# StarFive VisionFive 2 v1.3b register map
File version: 0.1
Registers are 32-bit, read-write, no defined reset value unless marked. A register's access mark holds for its fields unless they carry their own. Offsets are from the block's base; [hi:lo] are bit positions; {n}, {i} and the like mark numbered series.

## starfive_jh7110_sys_pinctrl_0 (part 3 of 3) — From starfive,jh7110-sys-pinctrl, peripheral generator
Base 0x13040000
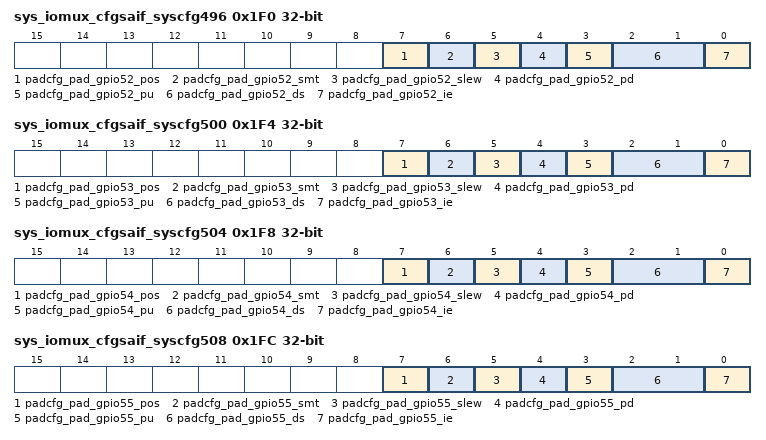
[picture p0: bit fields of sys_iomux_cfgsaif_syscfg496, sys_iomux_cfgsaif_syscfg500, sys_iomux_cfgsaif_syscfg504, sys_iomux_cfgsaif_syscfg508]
0x1F0 sys_iomux_cfgsaif_syscfg496
  [7] padcfg_pad_gpio52_pos — Power-on-Start (POS) enabler - 1: Enable active pull down for loss of core power, 0: Active pull-down capability disabled
  [6] padcfg_pad_gpio52_smt — Active high Schmitt (SMT) trigger selector - 0: No hysteresis, 1: Schmitt trigger ebabled
  [5] padcfg_pad_gpio52_slew — Slew Rate Control - 0: Slow (Half frequency), 1: Fast
  [4] padcfg_pad_gpio52_pd — Pull-Down (PD) settings - 1: Yes, 0: No
  [3] padcfg_pad_gpio52_pu — Pull-Up (PU) settings - 1: Yes, 0: No
  [2:1] padcfg_pad_gpio52_ds — Output Drive Strength (DS) - 00: The rated drive strength is 2 mA, 01: The rated drive strength is 4 mA, 10: The rated drive strength is 8 mA, 11: The rated drive strength is 12 mA
  [0] padcfg_pad_gpio52_ie — Input Enable (IE) Controller - 1: Enable the receiver, 0: Disable the receiver
0x1F4 sys_iomux_cfgsaif_syscfg500
  [7] padcfg_pad_gpio53_pos — Power-on-Start (POS) enabler - 1: Enable active pull down for loss of core power, 0: Active pull-down capability disabled
  [6] padcfg_pad_gpio53_smt — Active high Schmitt (SMT) trigger selector - 0: No hysteresis, 1: Schmitt trigger ebabled
  [5] padcfg_pad_gpio53_slew — Slew Rate Control - 0: Slow (Half frequency), 1: Fast
  [4] padcfg_pad_gpio53_pd — Pull-Down (PD) settings - 1: Yes, 0: No
  [3] padcfg_pad_gpio53_pu — Pull-Up (PU) settings - 1: Yes, 0: No
  [2:1] padcfg_pad_gpio53_ds — Output Drive Strength (DS) - 00: The rated drive strength is 2 mA, 01: The rated drive strength is 4 mA, 10: The rated drive strength is 8 mA, 11: The rated drive strength is 12 mA
  [0] padcfg_pad_gpio53_ie — Input Enable (IE) Controller - 1: Enable the receiver, 0: Disable the receiver
0x1F8 sys_iomux_cfgsaif_syscfg504
  [7] padcfg_pad_gpio54_pos — Power-on-Start (POS) enabler - 1: Enable active pull down for loss of core power, 0: Active pull-down capability disabled
  [6] padcfg_pad_gpio54_smt — Active high Schmitt (SMT) trigger selector - 0: No hysteresis, 1: Schmitt trigger ebabled
  [5] padcfg_pad_gpio54_slew — Slew Rate Control - 0: Slow (Half frequency), 1: Fast
  [4] padcfg_pad_gpio54_pd — Pull-Down (PD) settings - 1: Yes, 0: No
  [3] padcfg_pad_gpio54_pu — Pull-Up (PU) settings - 1: Yes, 0: No
  [2:1] padcfg_pad_gpio54_ds — Output Drive Strength (DS) - 00: The rated drive strength is 2 mA, 01: The rated drive strength is 4 mA, 10: The rated drive strength is 8 mA, 11: The rated drive strength is 12 mA
  [0] padcfg_pad_gpio54_ie — Input Enable (IE) Controller - 1: Enable the receiver, 0: Disable the receiver
0x1FC sys_iomux_cfgsaif_syscfg508
  [7] padcfg_pad_gpio55_pos — Power-on-Start (POS) enabler - 1: Enable active pull down for loss of core power, 0: Active pull-down capability disabled
  [6] padcfg_pad_gpio55_smt — Active high Schmitt (SMT) trigger selector - 0: No hysteresis, 1: Schmitt trigger ebabled
  [5] padcfg_pad_gpio55_slew — Slew Rate Control - 0: Slow (Half frequency), 1: Fast
  [4] padcfg_pad_gpio55_pd — Pull-Down (PD) settings - 1: Yes, 0: No
  [3] padcfg_pad_gpio55_pu — Pull-Up (PU) settings - 1: Yes, 0: No
  [2:1] padcfg_pad_gpio55_ds — Output Drive Strength (DS) - 00: The rated drive strength is 2 mA, 01: The rated drive strength is 4 mA, 10: The rated drive strength is 8 mA, 11: The rated drive strength is 12 mA
  [0] padcfg_pad_gpio55_ie — Input Enable (IE) Controller - 1: Enable the receiver, 0: Disable the receiver
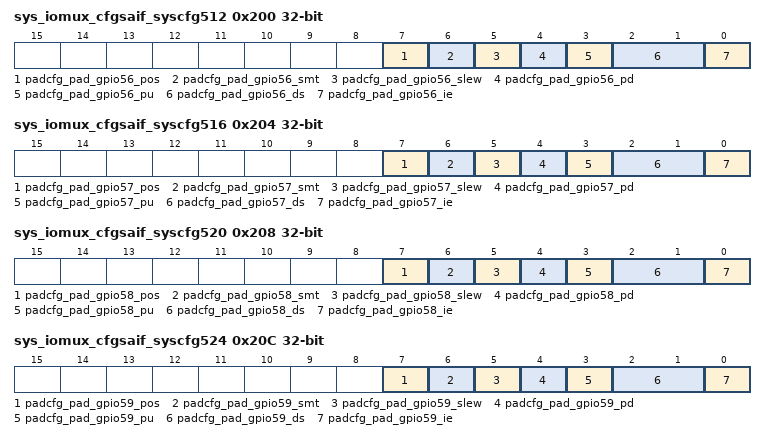
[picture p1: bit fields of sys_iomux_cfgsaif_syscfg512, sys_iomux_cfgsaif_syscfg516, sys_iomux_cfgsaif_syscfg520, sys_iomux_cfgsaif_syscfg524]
0x200 sys_iomux_cfgsaif_syscfg512
  [7] padcfg_pad_gpio56_pos — Power-on-Start (POS) enabler - 1: Enable active pull down for loss of core power, 0: Active pull-down capability disabled
  [6] padcfg_pad_gpio56_smt — Active high Schmitt (SMT) trigger selector - 0: No hysteresis, 1: Schmitt trigger ebabled
  [5] padcfg_pad_gpio56_slew — Slew Rate Control - 0: Slow (Half frequency), 1: Fast
  [4] padcfg_pad_gpio56_pd — Pull-Down (PD) settings - 1: Yes, 0: No
  [3] padcfg_pad_gpio56_pu — Pull-Up (PU) settings - 1: Yes, 0: No
  [2:1] padcfg_pad_gpio56_ds — Output Drive Strength (DS) - 00: The rated drive strength is 2 mA, 01: The rated drive strength is 4 mA, 10: The rated drive strength is 8 mA, 11: The rated drive strength is 12 mA
  [0] padcfg_pad_gpio56_ie — Input Enable (IE) Controller - 1: Enable the receiver, 0: Disable the receiver
0x204 sys_iomux_cfgsaif_syscfg516
  [7] padcfg_pad_gpio57_pos — Power-on-Start (POS) enabler - 1: Enable active pull down for loss of core power, 0: Active pull-down capability disabled
  [6] padcfg_pad_gpio57_smt — Active high Schmitt (SMT) trigger selector - 0: No hysteresis, 1: Schmitt trigger ebabled
  [5] padcfg_pad_gpio57_slew — Slew Rate Control - 0: Slow (Half frequency), 1: Fast
  [4] padcfg_pad_gpio57_pd — Pull-Down (PD) settings - 1: Yes, 0: No
  [3] padcfg_pad_gpio57_pu — Pull-Up (PU) settings - 1: Yes, 0: No
  [2:1] padcfg_pad_gpio57_ds — Output Drive Strength (DS) - 00: The rated drive strength is 2 mA, 01: The rated drive strength is 4 mA, 10: The rated drive strength is 8 mA, 11: The rated drive strength is 12 mA
  [0] padcfg_pad_gpio57_ie — Input Enable (IE) Controller - 1: Enable the receiver, 0: Disable the receiver
0x208 sys_iomux_cfgsaif_syscfg520
  [7] padcfg_pad_gpio58_pos — Power-on-Start (POS) enabler - 1: Enable active pull down for loss of core power, 0: Active pull-down capability disabled
  [6] padcfg_pad_gpio58_smt — Active high Schmitt (SMT) trigger selector - 0: No hysteresis, 1: Schmitt trigger ebabled
  [5] padcfg_pad_gpio58_slew — Slew Rate Control - 0: Slow (Half frequency), 1: Fast
  [4] padcfg_pad_gpio58_pd — Pull-Down (PD) settings - 1: Yes, 0: No
  [3] padcfg_pad_gpio58_pu — Pull-Up (PU) settings - 1: Yes, 0: No
  [2:1] padcfg_pad_gpio58_ds — Output Drive Strength (DS) - 00: The rated drive strength is 2 mA, 01: The rated drive strength is 4 mA, 10: The rated drive strength is 8 mA, 11: The rated drive strength is 12 mA
  [0] padcfg_pad_gpio58_ie — Input Enable (IE) Controller - 1: Enable the receiver, 0: Disable the receiver
0x20C sys_iomux_cfgsaif_syscfg524
  [7] padcfg_pad_gpio59_pos — Power-on-Start (POS) enabler - 1: Enable active pull down for loss of core power, 0: Active pull-down capability disabled
  [6] padcfg_pad_gpio59_smt — Active high Schmitt (SMT) trigger selector - 0: No hysteresis, 1: Schmitt trigger ebabled
  [5] padcfg_pad_gpio59_slew — Slew Rate Control - 0: Slow (Half frequency), 1: Fast
  [4] padcfg_pad_gpio59_pd — Pull-Down (PD) settings - 1: Yes, 0: No
  [3] padcfg_pad_gpio59_pu — Pull-Up (PU) settings - 1: Yes, 0: No
  [2:1] padcfg_pad_gpio59_ds — Output Drive Strength (DS) - 00: The rated drive strength is 2 mA, 01: The rated drive strength is 4 mA, 10: The rated drive strength is 8 mA, 11: The rated drive strength is 12 mA
  [0] padcfg_pad_gpio59_ie — Input Enable (IE) Controller - 1: Enable the receiver, 0: Disable the receiver
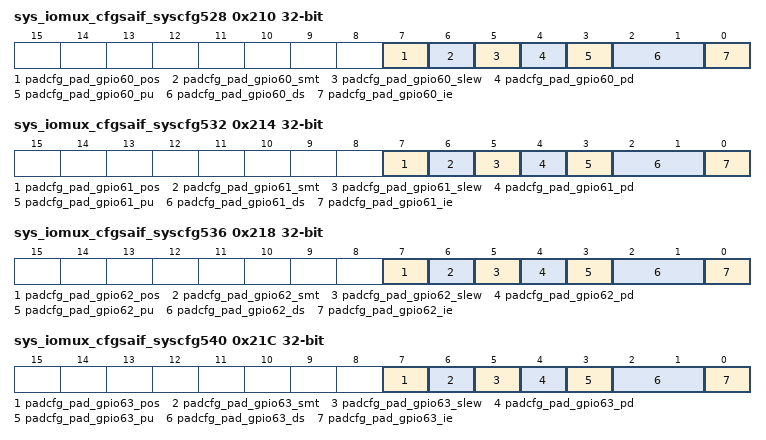
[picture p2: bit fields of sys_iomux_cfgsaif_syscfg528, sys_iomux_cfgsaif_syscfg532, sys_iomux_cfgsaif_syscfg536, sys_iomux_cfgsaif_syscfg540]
0x210 sys_iomux_cfgsaif_syscfg528
  [7] padcfg_pad_gpio60_pos — Power-on-Start (POS) enabler - 1: Enable active pull down for loss of core power, 0: Active pull-down capability disabled
  [6] padcfg_pad_gpio60_smt — Active high Schmitt (SMT) trigger selector - 0: No hysteresis, 1: Schmitt trigger ebabled
  [5] padcfg_pad_gpio60_slew — Slew Rate Control - 0: Slow (Half frequency), 1: Fast
  [4] padcfg_pad_gpio60_pd — Pull-Down (PD) settings - 1: Yes, 0: No
  [3] padcfg_pad_gpio60_pu — Pull-Up (PU) settings - 1: Yes, 0: No
  [2:1] padcfg_pad_gpio60_ds — Output Drive Strength (DS) - 00: The rated drive strength is 2 mA, 01: The rated drive strength is 4 mA, 10: The rated drive strength is 8 mA, 11: The rated drive strength is 12 mA
  [0] padcfg_pad_gpio60_ie — Input Enable (IE) Controller - 1: Enable the receiver, 0: Disable the receiver
0x214 sys_iomux_cfgsaif_syscfg532
  [7] padcfg_pad_gpio61_pos — Power-on-Start (POS) enabler - 1: Enable active pull down for loss of core power, 0: Active pull-down capability disabled
  [6] padcfg_pad_gpio61_smt — Active high Schmitt (SMT) trigger selector - 0: No hysteresis, 1: Schmitt trigger ebabled
  [5] padcfg_pad_gpio61_slew — Slew Rate Control - 0: Slow (Half frequency), 1: Fast
  [4] padcfg_pad_gpio61_pd — Pull-Down (PD) settings - 1: Yes, 0: No
  [3] padcfg_pad_gpio61_pu — Pull-Up (PU) settings - 1: Yes, 0: No
  [2:1] padcfg_pad_gpio61_ds — Output Drive Strength (DS) - 00: The rated drive strength is 2 mA, 01: The rated drive strength is 4 mA, 10: The rated drive strength is 8 mA, 11: The rated drive strength is 12 mA
  [0] padcfg_pad_gpio61_ie — Input Enable (IE) Controller - 1: Enable the receiver, 0: Disable the receiver
0x218 sys_iomux_cfgsaif_syscfg536
  [7] padcfg_pad_gpio62_pos — Power-on-Start (POS) enabler - 1: Enable active pull down for loss of core power, 0: Active pull-down capability disabled
  [6] padcfg_pad_gpio62_smt — Active high Schmitt (SMT) trigger selector - 0: No hysteresis, 1: Schmitt trigger ebabled
  [5] padcfg_pad_gpio62_slew — Slew Rate Control - 0: Slow (Half frequency), 1: Fast
  [4] padcfg_pad_gpio62_pd — Pull-Down (PD) settings - 1: Yes, 0: No
  [3] padcfg_pad_gpio62_pu — Pull-Up (PU) settings - 1: Yes, 0: No
  [2:1] padcfg_pad_gpio62_ds — Output Drive Strength (DS) - 00: The rated drive strength is 2 mA, 01: The rated drive strength is 4 mA, 10: The rated drive strength is 8 mA, 11: The rated drive strength is 12 mA
  [0] padcfg_pad_gpio62_ie — Input Enable (IE) Controller - 1: Enable the receiver, 0: Disable the receiver
0x21C sys_iomux_cfgsaif_syscfg540
  [7] padcfg_pad_gpio63_pos — Power-on-Start (POS) enabler - 1: Enable active pull down for loss of core power, 0: Active pull-down capability disabled
  [6] padcfg_pad_gpio63_smt — Active high Schmitt (SMT) trigger selector - 0: No hysteresis, 1: Schmitt trigger ebabled
  [5] padcfg_pad_gpio63_slew — Slew Rate Control - 0: Slow (Half frequency), 1: Fast
  [4] padcfg_pad_gpio63_pd — Pull-Down (PD) settings - 1: Yes, 0: No
  [3] padcfg_pad_gpio63_pu — Pull-Up (PU) settings - 1: Yes, 0: No
  [2:1] padcfg_pad_gpio63_ds — Output Drive Strength (DS) - 00: The rated drive strength is 2 mA, 01: The rated drive strength is 4 mA, 10: The rated drive strength is 8 mA, 11: The rated drive strength is 12 mA
  [0] padcfg_pad_gpio63_ie — Input Enable (IE) Controller - 1: Enable the receiver, 0: Disable the receiver
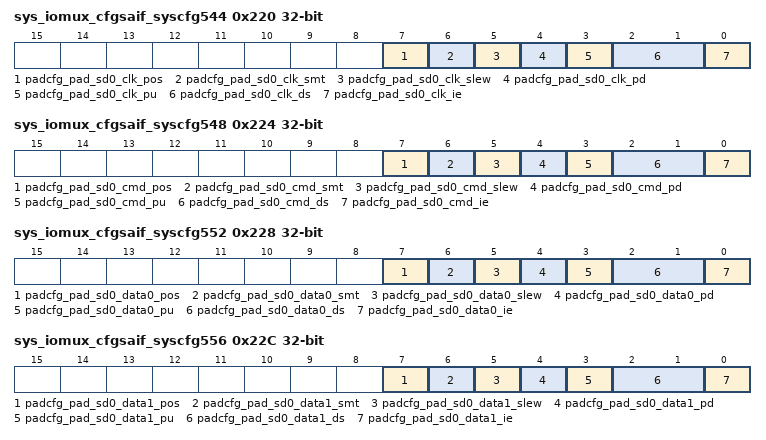
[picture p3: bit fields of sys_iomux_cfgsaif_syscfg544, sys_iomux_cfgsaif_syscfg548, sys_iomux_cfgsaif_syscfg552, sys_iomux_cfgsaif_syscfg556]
0x220 sys_iomux_cfgsaif_syscfg544
  [7] padcfg_pad_sd0_clk_pos — Power-on-Start (POS) enabler - 1: Enable active pull down for loss of core power, 0: Active pull-down capability disabled
  [6] padcfg_pad_sd0_clk_smt — Active high Schmitt (SMT) trigger selector - 0: No hysteresis, 1: Schmitt trigger ebabled
  [5] padcfg_pad_sd0_clk_slew — Slew Rate Control - 0: Slow (Half frequency), 1: Fast
  [4] padcfg_pad_sd0_clk_pd — Pull-Down (PD) settings - 1: Yes, 0: No
  [3] padcfg_pad_sd0_clk_pu — Pull-Up (PU) settings - 1: Yes, 0: No
  [2:1] padcfg_pad_sd0_clk_ds — Output Drive Strength (DS) - 00: The rated drive strength is 2 mA, 01: The rated drive strength is 4 mA, 10: The rated drive strength is 8 mA, 11: The rated drive strength is 12 mA
  [0] padcfg_pad_sd0_clk_ie — Input Enable (IE) Controller - 1: Enable the receiver, 0: Disable the receiver
0x224 sys_iomux_cfgsaif_syscfg548
  [7] padcfg_pad_sd0_cmd_pos — Power-on-Start (POS) enabler - 1: Enable active pull down for loss of core power, 0: Active pull-down capability disabled
  [6] padcfg_pad_sd0_cmd_smt — Active high Schmitt (SMT) trigger selector - 0: No hysteresis, 1: Schmitt trigger ebabled
  [5] padcfg_pad_sd0_cmd_slew — Slew Rate Control - 0: Slow (Half frequency), 1: Fast
  [4] padcfg_pad_sd0_cmd_pd — Pull-Down (PD) settings - 1: Yes, 0: No
  [3] padcfg_pad_sd0_cmd_pu — Pull-Up (PU) settings - 1: Yes, 0: No
  [2:1] padcfg_pad_sd0_cmd_ds — Output Drive Strength (DS) - 00: The rated drive strength is 2 mA, 01: The rated drive strength is 4 mA, 10: The rated drive strength is 8 mA, 11: The rated drive strength is 12 mA
  [0] padcfg_pad_sd0_cmd_ie — Input Enable (IE) Controller - 1: Enable the receiver, 0: Disable the receiver
0x228 sys_iomux_cfgsaif_syscfg552
  [7] padcfg_pad_sd0_data0_pos — Power-on-Start (POS) enabler - 1: Enable active pull down for loss of core power, 0: Active pull-down capability disabled
  [6] padcfg_pad_sd0_data0_smt — Active high Schmitt (SMT) trigger selector - 0: No hysteresis, 1: Schmitt trigger ebabled
  [5] padcfg_pad_sd0_data0_slew — Slew Rate Control - 0: Slow (Half frequency), 1: Fast
  [4] padcfg_pad_sd0_data0_pd — Pull-Down (PD) settings - 1: Yes, 0: No
  [3] padcfg_pad_sd0_data0_pu — Pull-Up (PU) settings - 1: Yes, 0: No
  [2:1] padcfg_pad_sd0_data0_ds — Output Drive Strength (DS) - 00: The rated drive strength is 2 mA, 01: The rated drive strength is 4 mA, 10: The rated drive strength is 8 mA, 11: The rated drive strength is 12 mA
  [0] padcfg_pad_sd0_data0_ie — Input Enable (IE) Controller - 1: Enable the receiver, 0: Disable the receiver
0x22C sys_iomux_cfgsaif_syscfg556
  [7] padcfg_pad_sd0_data1_pos — Power-on-Start (POS) enabler - 1: Enable active pull down for loss of core power, 0: Active pull-down capability disabled
  [6] padcfg_pad_sd0_data1_smt — Active high Schmitt (SMT) trigger selector - 0: No hysteresis, 1: Schmitt trigger ebabled
  [5] padcfg_pad_sd0_data1_slew — Slew Rate Control - 0: Slow (Half frequency), 1: Fast
  [4] padcfg_pad_sd0_data1_pd — Pull-Down (PD) settings - 1: Yes, 0: No
  [3] padcfg_pad_sd0_data1_pu — Pull-Up (PU) settings - 1: Yes, 0: No
  [2:1] padcfg_pad_sd0_data1_ds — Output Drive Strength (DS) - 00: The rated drive strength is 2 mA, 01: The rated drive strength is 4 mA, 10: The rated drive strength is 8 mA, 11: The rated drive strength is 12 mA
  [0] padcfg_pad_sd0_data1_ie — Input Enable (IE) Controller - 1: Enable the receiver, 0: Disable the receiver
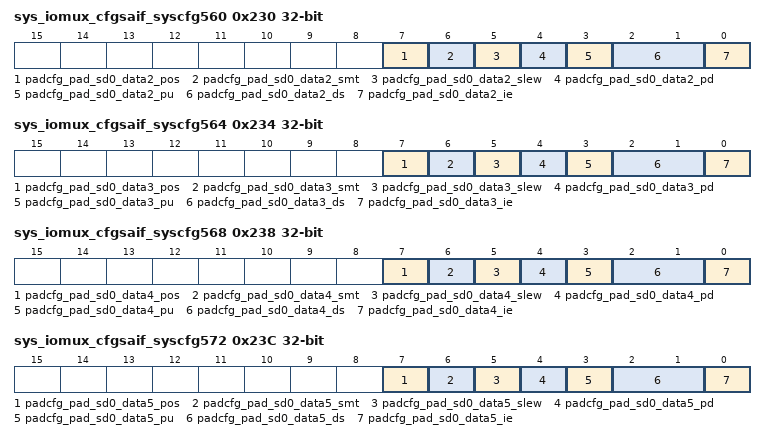
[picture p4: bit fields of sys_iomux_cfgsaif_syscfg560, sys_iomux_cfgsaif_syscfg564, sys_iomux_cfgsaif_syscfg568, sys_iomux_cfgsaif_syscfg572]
0x230 sys_iomux_cfgsaif_syscfg560
  [7] padcfg_pad_sd0_data2_pos — Power-on-Start (POS) enabler - 1: Enable active pull down for loss of core power, 0: Active pull-down capability disabled
  [6] padcfg_pad_sd0_data2_smt — Active high Schmitt (SMT) trigger selector - 0: No hysteresis, 1: Schmitt trigger ebabled
  [5] padcfg_pad_sd0_data2_slew — Slew Rate Control - 0: Slow (Half frequency), 1: Fast
  [4] padcfg_pad_sd0_data2_pd — Pull-Down (PD) settings - 1: Yes, 0: No
  [3] padcfg_pad_sd0_data2_pu — Pull-Up (PU) settings - 1: Yes, 0: No
  [2:1] padcfg_pad_sd0_data2_ds — Output Drive Strength (DS) - 00: The rated drive strength is 2 mA, 01: The rated drive strength is 4 mA, 10: The rated drive strength is 8 mA, 11: The rated drive strength is 12 mA
  [0] padcfg_pad_sd0_data2_ie — Input Enable (IE) Controller - 1: Enable the receiver, 0: Disable the receiver
0x234 sys_iomux_cfgsaif_syscfg564
  [7] padcfg_pad_sd0_data3_pos — Power-on-Start (POS) enabler - 1: Enable active pull down for loss of core power, 0: Active pull-down capability disabled
  [6] padcfg_pad_sd0_data3_smt — Active high Schmitt (SMT) trigger selector - 0: No hysteresis, 1: Schmitt trigger ebabled
  [5] padcfg_pad_sd0_data3_slew — Slew Rate Control - 0: Slow (Half frequency), 1: Fast
  [4] padcfg_pad_sd0_data3_pd — Pull-Down (PD) settings - 1: Yes, 0: No
  [3] padcfg_pad_sd0_data3_pu — Pull-Up (PU) settings - 1: Yes, 0: No
  [2:1] padcfg_pad_sd0_data3_ds — Output Drive Strength (DS) - 00: The rated drive strength is 2 mA, 01: The rated drive strength is 4 mA, 10: The rated drive strength is 8 mA, 11: The rated drive strength is 12 mA
  [0] padcfg_pad_sd0_data3_ie — Input Enable (IE) Controller - 1: Enable the receiver, 0: Disable the receiver
0x238 sys_iomux_cfgsaif_syscfg568
  [7] padcfg_pad_sd0_data4_pos — Power-on-Start (POS) enabler - 1: Enable active pull down for loss of core power, 0: Active pull-down capability disabled
  [6] padcfg_pad_sd0_data4_smt — Active high Schmitt (SMT) trigger selector - 0: No hysteresis, 1: Schmitt trigger ebabled
  [5] padcfg_pad_sd0_data4_slew — Slew Rate Control - 0: Slow (Half frequency), 1: Fast
  [4] padcfg_pad_sd0_data4_pd — Pull-Down (PD) settings - 1: Yes, 0: No
  [3] padcfg_pad_sd0_data4_pu — Pull-Up (PU) settings - 1: Yes, 0: No
  [2:1] padcfg_pad_sd0_data4_ds — Output Drive Strength (DS) - 00: The rated drive strength is 2 mA, 01: The rated drive strength is 4 mA, 10: The rated drive strength is 8 mA, 11: The rated drive strength is 12 mA
  [0] padcfg_pad_sd0_data4_ie — Input Enable (IE) Controller - 1: Enable the receiver, 0: Disable the receiver
0x23C sys_iomux_cfgsaif_syscfg572
  [7] padcfg_pad_sd0_data5_pos — Power-on-Start (POS) enabler - 1: Enable active pull down for loss of core power, 0: Active pull-down capability disabled
  [6] padcfg_pad_sd0_data5_smt — Active high Schmitt (SMT) trigger selector - 0: No hysteresis, 1: Schmitt trigger ebabled
  [5] padcfg_pad_sd0_data5_slew — Slew Rate Control - 0: Slow (Half frequency), 1: Fast
  [4] padcfg_pad_sd0_data5_pd — Pull-Down (PD) settings - 1: Yes, 0: No
  [3] padcfg_pad_sd0_data5_pu — Pull-Up (PU) settings - 1: Yes, 0: No
  [2:1] padcfg_pad_sd0_data5_ds — Output Drive Strength (DS) - 00: The rated drive strength is 2 mA, 01: The rated drive strength is 4 mA, 10: The rated drive strength is 8 mA, 11: The rated drive strength is 12 mA
  [0] padcfg_pad_sd0_data5_ie — Input Enable (IE) Controller - 1: Enable the receiver, 0: Disable the receiver
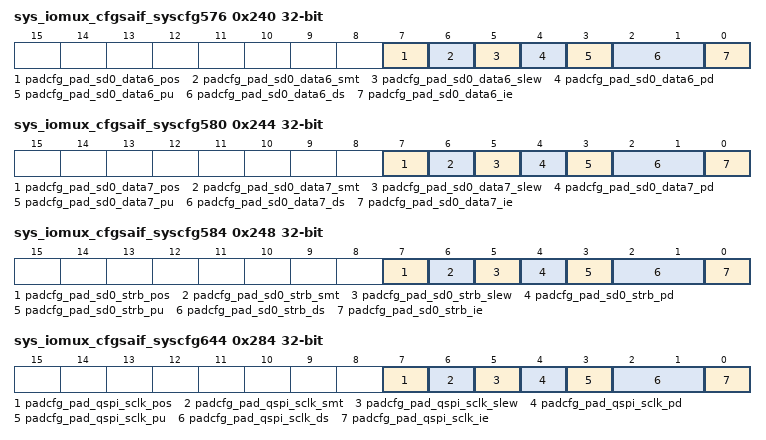
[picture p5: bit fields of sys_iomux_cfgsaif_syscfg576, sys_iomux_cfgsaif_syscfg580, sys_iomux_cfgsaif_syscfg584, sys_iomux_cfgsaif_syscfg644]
0x240 sys_iomux_cfgsaif_syscfg576
  [7] padcfg_pad_sd0_data6_pos — Power-on-Start (POS) enabler - 1: Enable active pull down for loss of core power, 0: Active pull-down capability disabled
  [6] padcfg_pad_sd0_data6_smt — Active high Schmitt (SMT) trigger selector - 0: No hysteresis, 1: Schmitt trigger ebabled
  [5] padcfg_pad_sd0_data6_slew — Slew Rate Control - 0: Slow (Half frequency), 1: Fast
  [4] padcfg_pad_sd0_data6_pd — Pull-Down (PD) settings - 1: Yes, 0: No
  [3] padcfg_pad_sd0_data6_pu — Pull-Up (PU) settings - 1: Yes, 0: No
  [2:1] padcfg_pad_sd0_data6_ds — Output Drive Strength (DS) - 00: The rated drive strength is 2 mA, 01: The rated drive strength is 4 mA, 10: The rated drive strength is 8 mA, 11: The rated drive strength is 12 mA
  [0] padcfg_pad_sd0_data6_ie — Input Enable (IE) Controller - 1: Enable the receiver, 0: Disable the receiver
0x244 sys_iomux_cfgsaif_syscfg580
  [7] padcfg_pad_sd0_data7_pos — Power-on-Start (POS) enabler - 1: Enable active pull down for loss of core power, 0: Active pull-down capability disabled
  [6] padcfg_pad_sd0_data7_smt — Active high Schmitt (SMT) trigger selector - 0: No hysteresis, 1: Schmitt trigger ebabled
  [5] padcfg_pad_sd0_data7_slew — Slew Rate Control - 0: Slow (Half frequency), 1: Fast
  [4] padcfg_pad_sd0_data7_pd — Pull-Down (PD) settings - 1: Yes, 0: No
  [3] padcfg_pad_sd0_data7_pu — Pull-Up (PU) settings - 1: Yes, 0: No
  [2:1] padcfg_pad_sd0_data7_ds — Output Drive Strength (DS) - 00: The rated drive strength is 2 mA, 01: The rated drive strength is 4 mA, 10: The rated drive strength is 8 mA, 11: The rated drive strength is 12 mA
  [0] padcfg_pad_sd0_data7_ie — Input Enable (IE) Controller - 1: Enable the receiver, 0: Disable the receiver
0x248 sys_iomux_cfgsaif_syscfg584
  [7] padcfg_pad_sd0_strb_pos — Power-on-Start (POS) enabler - 1: Enable active pull down for loss of core power, 0: Active pull-down capability disabled
  [6] padcfg_pad_sd0_strb_smt — Active high Schmitt (SMT) trigger selector - 0: No hysteresis, 1: Schmitt trigger ebabled
  [5] padcfg_pad_sd0_strb_slew — Slew Rate Control - 0: Slow (Half frequency), 1: Fast
  [4] padcfg_pad_sd0_strb_pd — Pull-Down (PD) settings - 1: Yes, 0: No
  [3] padcfg_pad_sd0_strb_pu — Pull-Up (PU) settings - 1: Yes, 0: No
  [2:1] padcfg_pad_sd0_strb_ds — Output Drive Strength (DS) - 00: The rated drive strength is 2 mA, 01: The rated drive strength is 4 mA, 10: The rated drive strength is 8 mA, 11: The rated drive strength is 12 mA
  [0] padcfg_pad_sd0_strb_ie — Input Enable (IE) Controller - 1: Enable the receiver, 0: Disable the receiver
0x24C sys_iomux_cfgsaif_syscfg588
  [1:0] padcfg_pad_gmac1_mdc_syscon
0x250 sys_iomux_cfgsaif_syscfg592
  [1:0] padcfg_pad_gmac1_mdio_syscon
0x254 sys_iomux_cfgsaif_syscfg596
  [1:0] padcfg_pad_gmac1_rxd0_syscon
0x258 sys_iomux_cfgsaif_syscfg600
  [1:0] padcfg_pad_gmac1_rxd1_syscon
0x25C sys_iomux_cfgsaif_syscfg604
  [1:0] padcfg_pad_gmac1_rxd2_syscon
0x260 sys_iomux_cfgsaif_syscfg608
  [1:0] padcfg_pad_gmac1_rxd3_syscon
0x264 sys_iomux_cfgsaif_syscfg612
  [1:0] padcfg_pad_gmac1_rxdv_syscon
0x268 sys_iomux_cfgsaif_syscfg616
  [1:0] padcfg_pad_gmac1_rxc_syscon
0x26C sys_iomux_cfgsaif_syscfg620
  [1:0] padcfg_pad_gmac1_txd0_syscon
0x270 sys_iomux_cfgsaif_syscfg624
  [1:0] padcfg_pad_gmac1_txd1_syscon
0x274 sys_iomux_cfgsaif_syscfg628
  [1:0] padcfg_pad_gmac1_txd2_syscon
0x278 sys_iomux_cfgsaif_syscfg632
  [1:0] padcfg_pad_gmac1_txd3_syscon
0x27C sys_iomux_cfgsaif_syscfg636
  [1:0] padcfg_pad_gmac1_txen_syscon
0x280 sys_iomux_cfgsaif_syscfg640
  [1:0] padcfg_pad_gmac1_txc_syscon
0x284 sys_iomux_cfgsaif_syscfg644
  [7] padcfg_pad_qspi_sclk_pos — Power-on-Start (POS) enabler - 1: Enable active pull down for loss of core power, 0: Active pull-down capability disabled
  [6] padcfg_pad_qspi_sclk_smt — Active high Schmitt (SMT) trigger selector - 0: No hysteresis, 1: Schmitt trigger ebabled
  [5] padcfg_pad_qspi_sclk_slew — Slew Rate Control - 0: Slow (Half frequency), 1: Fast
  [4] padcfg_pad_qspi_sclk_pd — Pull-Down (PD) settings - 1: Yes, 0: No
  [3] padcfg_pad_qspi_sclk_pu — Pull-Up (PU) settings - 1: Yes, 0: No
  [2:1] padcfg_pad_qspi_sclk_ds — Output Drive Strength (DS) - 00: The rated drive strength is 2 mA, 01: The rated drive strength is 4 mA, 10: The rated drive strength is 8 mA, 11: The rated drive strength is 12 mA
  [0] padcfg_pad_qspi_sclk_ie — Input Enable (IE) Controller - 1: Enable the receiver, 0: Disable the receiver
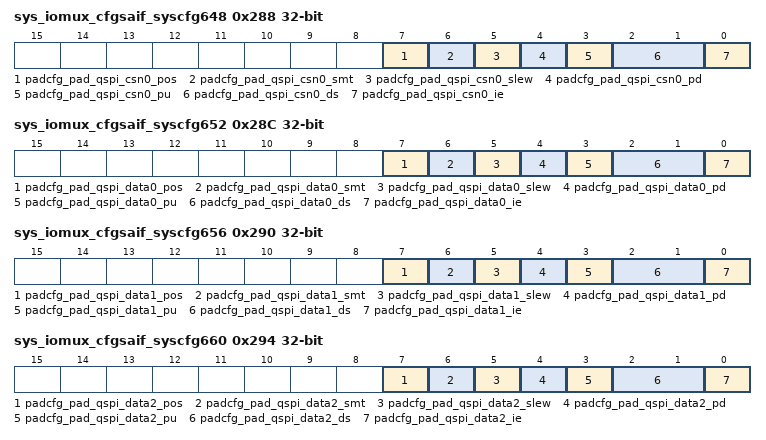
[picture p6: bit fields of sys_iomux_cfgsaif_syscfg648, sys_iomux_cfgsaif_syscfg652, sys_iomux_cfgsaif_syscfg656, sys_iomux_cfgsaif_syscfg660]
0x288 sys_iomux_cfgsaif_syscfg648
  [7] padcfg_pad_qspi_csn0_pos — Power-on-Start (POS) enabler - 1: Enable active pull down for loss of core power, 0: Active pull-down capability disabled
  [6] padcfg_pad_qspi_csn0_smt — Active high Schmitt (SMT) trigger selector - 0: No hysteresis, 1: Schmitt trigger ebabled
  [5] padcfg_pad_qspi_csn0_slew — Slew Rate Control - 0: Slow (Half frequency), 1: Fast
  [4] padcfg_pad_qspi_csn0_pd — Pull-Down (PD) settings - 1: Yes, 0: No
  [3] padcfg_pad_qspi_csn0_pu — Pull-Up (PU) settings - 1: Yes, 0: No
  [2:1] padcfg_pad_qspi_csn0_ds — Output Drive Strength (DS) - 00: The rated drive strength is 2 mA, 01: The rated drive strength is 4 mA, 10: The rated drive strength is 8 mA, 11: The rated drive strength is 12 mA
  [0] padcfg_pad_qspi_csn0_ie — Input Enable (IE) Controller - 1: Enable the receiver, 0: Disable the receiver
0x28C sys_iomux_cfgsaif_syscfg652
  [7] padcfg_pad_qspi_data0_pos — Power-on-Start (POS) enabler - 1: Enable active pull down for loss of core power, 0: Active pull-down capability disabled
  [6] padcfg_pad_qspi_data0_smt — Active high Schmitt (SMT) trigger selector - 0: No hysteresis, 1: Schmitt trigger ebabled
  [5] padcfg_pad_qspi_data0_slew — Slew Rate Control - 0: Slow (Half frequency), 1: Fast
  [4] padcfg_pad_qspi_data0_pd — Pull-Down (PD) settings - 1: Yes, 0: No
  [3] padcfg_pad_qspi_data0_pu — Pull-Up (PU) settings - 1: Yes, 0: No
  [2:1] padcfg_pad_qspi_data0_ds — Output Drive Strength (DS) - 00: The rated drive strength is 2 mA, 01: The rated drive strength is 4 mA, 10: The rated drive strength is 8 mA, 11: The rated drive strength is 12 mA
  [0] padcfg_pad_qspi_data0_ie — Input Enable (IE) Controller - 1: Enable the receiver, 0: Disable the receiver
0x290 sys_iomux_cfgsaif_syscfg656
  [7] padcfg_pad_qspi_data1_pos — Power-on-Start (POS) enabler - 1: Enable active pull down for loss of core power, 0: Active pull-down capability disabled
  [6] padcfg_pad_qspi_data1_smt — Active high Schmitt (SMT) trigger selector - 0: No hysteresis, 1: Schmitt trigger ebabled
  [5] padcfg_pad_qspi_data1_slew — Slew Rate Control - 0: Slow (Half frequency), 1: Fast
  [4] padcfg_pad_qspi_data1_pd — Pull-Down (PD) settings - 1: Yes, 0: No
  [3] padcfg_pad_qspi_data1_pu — Pull-Up (PU) settings - 1: Yes, 0: No
  [2:1] padcfg_pad_qspi_data1_ds — Output Drive Strength (DS) - 00: The rated drive strength is 2 mA, 01: The rated drive strength is 4 mA, 10: The rated drive strength is 8 mA, 11: The rated drive strength is 12 mA
  [0] padcfg_pad_qspi_data1_ie — Input Enable (IE) Controller - 1: Enable the receiver, 0: Disable the receiver
0x294 sys_iomux_cfgsaif_syscfg660
  [7] padcfg_pad_qspi_data2_pos — Power-on-Start (POS) enabler - 1: Enable active pull down for loss of core power, 0: Active pull-down capability disabled
  [6] padcfg_pad_qspi_data2_smt — Active high Schmitt (SMT) trigger selector - 0: No hysteresis, 1: Schmitt trigger ebabled
  [5] padcfg_pad_qspi_data2_slew — Slew Rate Control - 0: Slow (Half frequency), 1: Fast
  [4] padcfg_pad_qspi_data2_pd — Pull-Down (PD) settings - 1: Yes, 0: No
  [3] padcfg_pad_qspi_data2_pu — Pull-Up (PU) settings - 1: Yes, 0: No
  [2:1] padcfg_pad_qspi_data2_ds — Output Drive Strength (DS) - 00: The rated drive strength is 2 mA, 01: The rated drive strength is 4 mA, 10: The rated drive strength is 8 mA, 11: The rated drive strength is 12 mA
  [0] padcfg_pad_qspi_data2_ie — Input Enable (IE) Controller - 1: Enable the receiver, 0: Disable the receiver
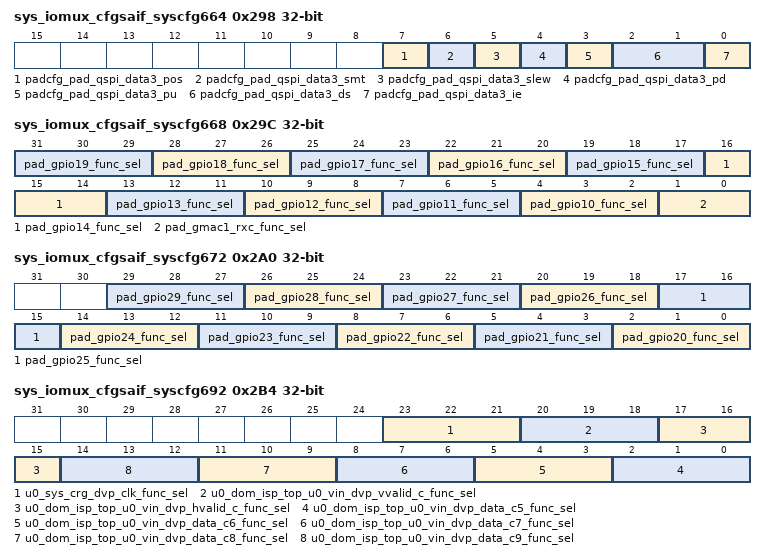
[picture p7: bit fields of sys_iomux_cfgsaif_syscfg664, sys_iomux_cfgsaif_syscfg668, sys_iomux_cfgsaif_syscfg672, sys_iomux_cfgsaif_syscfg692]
0x298 sys_iomux_cfgsaif_syscfg664
  [7] padcfg_pad_qspi_data3_pos — Power-on-Start (POS) enabler - 1: Enable active pull down for loss of core power, 0: Active pull-down capability disabled
  [6] padcfg_pad_qspi_data3_smt — Active high Schmitt (SMT) trigger selector - 0: No hysteresis, 1: Schmitt trigger ebabled
  [5] padcfg_pad_qspi_data3_slew — Slew Rate Control - 0: Slow (Half frequency), 1: Fast
  [4] padcfg_pad_qspi_data3_pd — Pull-Down (PD) settings - 1: Yes, 0: No
  [3] padcfg_pad_qspi_data3_pu — Pull-Up (PU) settings - 1: Yes, 0: No
  [2:1] padcfg_pad_qspi_data3_ds — Output Drive Strength (DS) - 00: The rated drive strength is 2 mA, 01: The rated drive strength is 4 mA, 10: The rated drive strength is 8 mA, 11: The rated drive strength is 12 mA
  [0] padcfg_pad_qspi_data3_ie — Input Enable (IE) Controller - 1: Enable the receiver, 0: Disable the receiver
0x29C sys_iomux_cfgsaif_syscfg668
  [3n-26:3n-28] pad_gpio{n}_func_sel (n=10..19) — GPIO function selector: * Function 0: See Function Description no page 84 for more information, * Function 1: See Full Multiplexing for more information, * Function 2: See Function 2 for more information, * Function 3: See Function 3 for more information
  [1:0] pad_gmac1_rxc_func_sel — Function selector of GMAC1_RXC: * Function 0: u0_sys_crg.clk_gmac1_rgmii_rx, * Function 1: u0_sys_crg.clk_gmac1_rmii_ref, * Function 2: None, * Function 3: None
0x2A0 sys_iomux_cfgsaif_syscfg672
  [3n-58:3n-60] pad_gpio{n}_func_sel (n=20..29) — GPIO function selector: * Function 0: See Function Description no page 84 for more information, * Function 1: See Full Multiplexing for more information, * Function 2: See Function 2 for more information, * Function 3: See Function 3 for more information
0x2A4 sys_iomux_cfgsaif_syscfg676
  [3n-88:3n-90] pad_gpio{n}_func_sel (n=30..40) — GPIO function selector: * Function 0: See Function Description no page 84 for more information, * Function 1: See Full Multiplexing for more information, * Function 2: See Function 2 for more information, * Function 3: See Function 3 for more information
0x2A8 sys_iomux_cfgsaif_syscfg680
  [3n-121:3n-123] pad_gpio{n}_func_sel (n=41..51) — GPIO function selector: * Function 0: See Function Description no page 84 for more information, * Function 1: See Full Multiplexing for more information, * Function 2: See Function 2 for more information, * Function 3: See Function 3 for more information
0x2AC sys_iomux_cfgsaif_syscfg684
  [3n-154:3n-156] pad_gpio{n}_func_sel (n=56..62) — GPIO function selector: * Function 0: See Function Description no page 84 for more information, * Function 1: See Full Multiplexing for more information, * Function 2: See Function 2 for more information, * Function 3: See Function 3 for more information
  [31:30] pad_gpio63_func_sel — GPIO function selector: * Function 0: See Function Description no page 84 for more information, * Function 1: See Full Multiplexing for more information, * Function 2: See Function 2 for more information, * Function 3: See Function 3 for more information
  [5:4] pad_gpio54_func_sel — GPIO function selector: * Function 0: See Function Description no page 84 for more information, * Function 1: See Full Multiplexing for more information, * Function 2: See Function 2 for more information, * Function 3: See Function 3 for more information
  [3:2] pad_gpio53_func_sel — GPIO function selector: * Function 0: See Function Description no page 84 for more information, * Function 1: See Full Multiplexing for more information, * Function 2: See Function 2 for more information, * Function 3: See Function 3 for more information
  [1:0] pad_gpio52_func_sel — GPIO function selector: * Function 0: See Function Description no page 84 for more information, * Function 1: See Full Multiplexing for more information, * Function 2: See Function 2 for more information, * Function 3: See Function 3 for more information
0x2B0 sys_iomux_cfgsaif_syscfg688
  [3n+19:3n+17] u0_dom_isp_top_u0_vin_dvp_data_c{n}_func_sel (n=1..4) — Function Selector of DVP_DATA[idx], see Function 2 for more information
  [19:17] u0_dom_isp_top_u0_vin_dvp_data_c11_func_sel — Function Selector of DVP_DATA[idx], see Function 2 for more information
  [16:14] u0_dom_isp_top_u0_vin_dvp_data_c10_func_sel — Function Selector of DVP_DATA[idx], see Function 2 for more information
  [13:11] u0_dom_isp_top_u0_vin_dvp_data_c0_func_sel — Function Selector of DVP_DATA[idx], see Function 2 for more information
  [11:9] pad_gpio9_func_sel — GPIO function selector: * Function 0: See Function Description no page 84 for more information, * Function 1: See Full Multiplexing for more information, * Function 2: See Function 2 for more information, * Function 3: See Function 3 for more information
  [8:6] pad_gpio8_func_sel — GPIO function selector: * Function 0: See Function Description no page 84 for more information, * Function 1: See Full Multiplexing for more information, * Function 2: See Function 2 for more information, * Function 3: See Function 3 for more information
  [5:3] pad_gpio7_func_sel — GPIO function selector: * Function 0: See Function Description no page 84 for more information, * Function 1: See Full Multiplexing for more information, * Function 2: See Function 2 for more information, * Function 3: See Function 3 for more information
  [1:0] pad_gpio6_func_sel — GPIO function selector: * Function 0: See Function Description no page 84 for more information, * Function 1: See Full Multiplexing for more information, * Function 2: See Function 2 for more information, * Function 3: See Function 3 for more information
0x2B4 sys_iomux_cfgsaif_syscfg692
  [23:21] u0_sys_crg_dvp_clk_func_sel — Function Selector of DVP_CLK, see Function 2 for more information
  [20:18] u0_dom_isp_top_u0_vin_dvp_vvalid_c_func_sel — Function Selector of DVP_VSYNC, see Function 2 for more information
  [17:15] u0_dom_isp_top_u0_vin_dvp_hvalid_c_func_sel — Function Selector of DVP_HSYNC, see Function 2 for more information
  [3n-13:3n-15] u0_dom_isp_top_u0_vin_dvp_data_c{n}_func_sel (n=5..9) — Function Selector of DVP_DATA[idx], see Function 2 for more information
